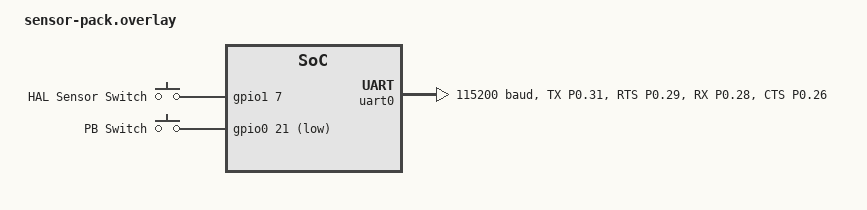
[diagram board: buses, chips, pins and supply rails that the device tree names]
/*
 * Copyright (c) 2022 Nordic Semiconductor ASA
 *
 * SPDX-License-Identifier: LicenseRef-Nordic-5-Clause
 */

 / {
	aliases {
		sw0 = &pw_sw;
	};


	trico_inputs {
		compatible = "gpio-keys";
		sw_hal: trico_input_0 {
			gpios = <&gpio1 7 GPIO_ACTIVE_HIGH>;
			label = "HAL Sensor Switch";
		};
		pw_sw: trico_input_1 {
			gpios = <&gpio0 21 GPIO_ACTIVE_LOW>;
			label = "PB Switch";
		};
	};	
};


&uart0 {
    current-speed = <115200>;
   pinctrl-0 = < &trico_console >;
   pinctrl-1 = < &trico_console_sleep >;
   pinctrl-names = "default", "sleep";
};

&pinctrl {
	
	trico_console: trico_console {
		group1 {
			psels = <NRF_PSEL(UART_TX, 0, 31)>,
					<NRF_PSEL(UART_RTS, 0, 29)>;
		};
		group2 {
			psels = <NRF_PSEL(UART_RX, 0, 28)>,
					<NRF_PSEL(UART_CTS, 0, 26)>;
			bias-pull-up;
		};
	};
	trico_console_sleep: trico_console_sleep {
		group1 {
			psels = <NRF_PSEL(UART_TX, 0, 31)>,
					<NRF_PSEL(UART_RX, 0, 28)>,
					<NRF_PSEL(UART_RTS, 0, 29)>,
					<NRF_PSEL(UART_CTS, 0, 26)>;
			low-power-enable;
		};
	};
	

};
